AUTOSAR XML (schema 4-0-3)
package /ComponentTypes
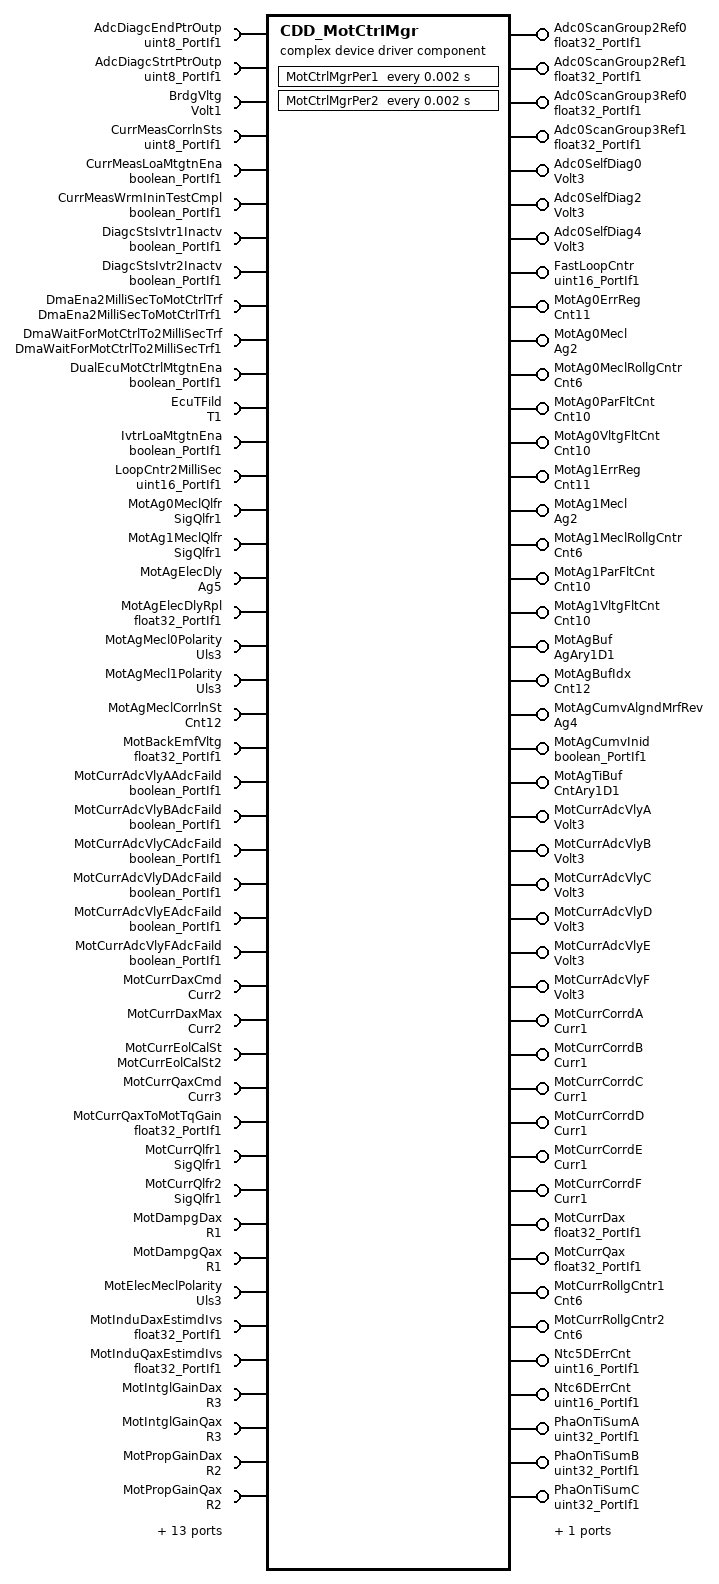
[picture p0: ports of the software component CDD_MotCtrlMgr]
  complex device driver sw component type CDD_MotCtrlMgr
    45 x provide port:
      Adc0ScanGroup2Ref0: nonqueued-sender-com-spec{data-element=Val, init-value=0}, provided-interface=float32_PortIf1
      Adc0ScanGroup2Ref1: nonqueued-sender-com-spec{data-element=Val, init-value=0}, provided-interface=float32_PortIf1
      Adc0ScanGroup3Ref0: nonqueued-sender-com-spec{data-element=Val, init-value=0}, provided-interface=float32_PortIf1
      Adc0ScanGroup3Ref1: nonqueued-sender-com-spec{data-element=Val, init-value=0}, provided-interface=float32_PortIf1
      Adc0SelfDiag0: nonqueued-sender-com-spec{data-element=Val, init-value=0}, provided-interface=Volt3
      Adc0SelfDiag2: nonqueued-sender-com-spec{data-element=Val, init-value=0}, provided-interface=Volt3
      Adc0SelfDiag4: nonqueued-sender-com-spec{data-element=Val, init-value=0}, provided-interface=Volt3
      FastLoopCntr: nonqueued-sender-com-spec{data-element=Val, init-value=0}, provided-interface=uint16_PortIf1
      MotAg0ErrReg: nonqueued-sender-com-spec{data-element=Val, init-value=0}, provided-interface=Cnt11
      MotAg0Mecl: nonqueued-sender-com-spec{data-element=Val, init-value=0}, provided-interface=Ag2
      MotAg0MeclRollgCntr: nonqueued-sender-com-spec{data-element=Val, init-value=0}, provided-interface=Cnt6
      MotAg0ParFltCnt: nonqueued-sender-com-spec{data-element=Val, init-value=0}, provided-interface=Cnt10
      MotAg0VltgFltCnt: nonqueued-sender-com-spec{data-element=Val, init-value=0}, provided-interface=Cnt10
      MotAg1ErrReg: nonqueued-sender-com-spec{data-element=Val, init-value=0}, provided-interface=Cnt11
      MotAg1Mecl: nonqueued-sender-com-spec{data-element=Val, init-value=0}, provided-interface=Ag2
      MotAg1MeclRollgCntr: nonqueued-sender-com-spec{data-element=Val, init-value=0}, provided-interface=Cnt6
      MotAg1ParFltCnt: nonqueued-sender-com-spec{data-element=Val, init-value=0}, provided-interface=Cnt10
      MotAg1VltgFltCnt: nonqueued-sender-com-spec{data-element=Val, init-value=0}, provided-interface=Cnt10
      MotAgBuf: nonqueued-sender-com-spec{data-element=Ary1D, init-value=8 x 0}, provided-interface=AgAry1D1
      MotAgBufIdx: nonqueued-sender-com-spec{data-element=Val, init-value=0}, provided-interface=Cnt12
      MotAgCumvAlgndMrfRev: nonqueued-sender-com-spec{data-element=Val, init-value=0}, provided-interface=Ag4
      MotAgCumvInid: nonqueued-sender-com-spec{data-element=Logl, init-value=0}, provided-interface=boolean_PortIf1
      MotAgTiBuf: nonqueued-sender-com-spec{data-element=Ary1D, init-value=8 x 0}, provided-interface=CntAry1D1
      MotCurrAdcVlyA: nonqueued-sender-com-spec{data-element=Val, init-value=0}, provided-interface=Volt3
      MotCurrAdcVlyB: nonqueued-sender-com-spec{data-element=Val, init-value=0}, provided-interface=Volt3
      MotCurrAdcVlyC: nonqueued-sender-com-spec{data-element=Val, init-value=0}, provided-interface=Volt3
      MotCurrAdcVlyD: nonqueued-sender-com-spec{data-element=Val, init-value=0}, provided-interface=Volt3
      MotCurrAdcVlyE: nonqueued-sender-com-spec{data-element=Val, init-value=0}, provided-interface=Volt3
      MotCurrAdcVlyF: nonqueued-sender-com-spec{data-element=Val, init-value=0}, provided-interface=Volt3
      MotCurrCorrdA: nonqueued-sender-com-spec{data-element=Val, init-value=0}, provided-interface=Curr1
      MotCurrCorrdB: nonqueued-sender-com-spec{data-element=Val, init-value=0}, provided-interface=Curr1
      MotCurrCorrdC: nonqueued-sender-com-spec{data-element=Val, init-value=0}, provided-interface=Curr1
      MotCurrCorrdD: nonqueued-sender-com-spec{data-element=Val, init-value=0}, provided-interface=Curr1
      MotCurrCorrdE: nonqueued-sender-com-spec{data-element=Val, init-value=0}, provided-interface=Curr1
      MotCurrCorrdF: nonqueued-sender-com-spec{data-element=Val, init-value=0}, provided-interface=Curr1
      MotCurrDax: nonqueued-sender-com-spec{data-element=Val, init-value=0}, provided-interface=float32_PortIf1
      MotCurrQax: nonqueued-sender-com-spec{data-element=Val, init-value=0}, provided-interface=float32_PortIf1
      MotCurrRollgCntr1: nonqueued-sender-com-spec{data-element=Val, init-value=0}, provided-interface=Cnt6
      MotCurrRollgCntr2: nonqueued-sender-com-spec{data-element=Val, init-value=0}, provided-interface=Cnt6
      Ntc5DErrCnt: nonqueued-sender-com-spec{data-element=Val, init-value=0}, provided-interface=uint16_PortIf1
      Ntc6DErrCnt: nonqueued-sender-com-spec{data-element=Val, init-value=0}, provided-interface=uint16_PortIf1
      PhaOnTiSumA: nonqueued-sender-com-spec{data-element=Val, init-value=0}, provided-interface=uint32_PortIf1
      PhaOnTiSumB: nonqueued-sender-com-spec{data-element=Val, init-value=0}, provided-interface=uint32_PortIf1
      PhaOnTiSumC: nonqueued-sender-com-spec{data-element=Val, init-value=0}, provided-interface=uint32_PortIf1
      SlowLoopCntr: nonqueued-sender-com-spec{data-element=Val, init-value=0}, provided-interface=uint16_PortIf1
    57 x require port:
      AdcDiagcEndPtrOutp: nonqueued-receiver-com-spec{data-element=Val, filter=data-filter-type=ALWAYS, init-value=23}, required-interface=uint8_PortIf1
      AdcDiagcStrtPtrOutp: nonqueued-receiver-com-spec{data-element=Val, filter=data-filter-type=ALWAYS, init-value=21}, required-interface=uint8_PortIf1
      BrdgVltg: nonqueued-receiver-com-spec{data-element=Val, filter=data-filter-type=ALWAYS, init-value=6}, required-interface=Volt1
      CurrMeasCorrlnSts: nonqueued-receiver-com-spec{data-element=Val, filter=data-filter-type=ALWAYS, init-value=63}, required-interface=uint8_PortIf1
      CurrMeasLoaMtgtnEna: nonqueued-receiver-com-spec{data-element=Logl, filter=data-filter-type=ALWAYS, init-value=0}, required-interface=boolean_PortIf1
      CurrMeasWrmIninTestCmpl: nonqueued-receiver-com-spec{data-element=Logl, filter=data-filter-type=ALWAYS, init-value=0}, required-interface=boolean_PortIf1
      DiagcStsIvtr1Inactv: nonqueued-receiver-com-spec{data-element=Logl, filter=data-filter-type=ALWAYS, init-value=0}, required-interface=boolean_PortIf1
      DiagcStsIvtr2Inactv: nonqueued-receiver-com-spec{data-element=Logl, filter=data-filter-type=ALWAYS, init-value=0}, required-interface=boolean_PortIf1
      DmaEna2MilliSecToMotCtrlTrf: client-com-spec=Oper, required-interface=DmaEna2MilliSecToMotCtrlTrf1
      DmaWaitForMotCtrlTo2MilliSecTrf: client-com-spec=Oper, required-interface=DmaWaitForMotCtrlTo2MilliSecTrf1
      DualEcuMotCtrlMtgtnEna: nonqueued-receiver-com-spec{data-element=Logl, filter=data-filter-type=ALWAYS, init-value=0}, required-interface=boolean_PortIf1
      EcuTFild: nonqueued-receiver-com-spec{data-element=Val, filter=data-filter-type=ALWAYS, init-value=25}, required-interface=T1
      IvtrLoaMtgtnEna: nonqueued-receiver-com-spec{data-element=Logl, filter=data-filter-type=ALWAYS, init-value=0}, required-interface=boolean_PortIf1
      LoopCntr2MilliSec: nonqueued-receiver-com-spec{data-element=Val, filter=data-filter-type=ALWAYS, init-value=0}, required-interface=uint16_PortIf1
      MotAg0MeclQlfr: nonqueued-receiver-com-spec{data-element=Val, filter=data-filter-type=ALWAYS, init-value=0}, required-interface=SigQlfr1
      MotAg1MeclQlfr: nonqueued-receiver-com-spec{data-element=Val, filter=data-filter-type=ALWAYS, init-value=0}, required-interface=SigQlfr1
      MotAgElecDly: nonqueued-receiver-com-spec{data-element=Val, filter=data-filter-type=ALWAYS, init-value=0}, required-interface=Ag5
      MotAgElecDlyRpl: nonqueued-receiver-com-spec{data-element=Val, filter=data-filter-type=ALWAYS, init-value=0}, required-interface=float32_PortIf1
      MotAgMecl0Polarity: nonqueued-receiver-com-spec{data-element=Val, filter=data-filter-type=ALWAYS, init-value=1}, required-interface=Uls3
      MotAgMecl1Polarity: nonqueued-receiver-com-spec{data-element=Val, filter=data-filter-type=ALWAYS, init-value=1}, required-interface=Uls3
      MotAgMeclCorrlnSt: nonqueued-receiver-com-spec{data-element=Val, filter=data-filter-type=ALWAYS, init-value=7}, required-interface=Cnt12
      MotBackEmfVltg: nonqueued-receiver-com-spec{data-element=Val, filter=data-filter-type=ALWAYS, init-value=0}, required-interface=float32_PortIf1
      MotCurrAdcVlyAAdcFaild: nonqueued-receiver-com-spec{data-element=Logl, filter=data-filter-type=ALWAYS, init-value=0}, required-interface=boolean_PortIf1
      MotCurrAdcVlyBAdcFaild: nonqueued-receiver-com-spec{data-element=Logl, filter=data-filter-type=ALWAYS, init-value=0}, required-interface=boolean_PortIf1
      MotCurrAdcVlyCAdcFaild: nonqueued-receiver-com-spec{data-element=Logl, filter=data-filter-type=ALWAYS, init-value=0}, required-interface=boolean_PortIf1
      MotCurrAdcVlyDAdcFaild: nonqueued-receiver-com-spec{data-element=Logl, filter=data-filter-type=ALWAYS, init-value=0}, required-interface=boolean_PortIf1
      MotCurrAdcVlyEAdcFaild: nonqueued-receiver-com-spec{data-element=Logl, filter=data-filter-type=ALWAYS, init-value=0}, required-interface=boolean_PortIf1
      MotCurrAdcVlyFAdcFaild: nonqueued-receiver-com-spec{data-element=Logl, filter=data-filter-type=ALWAYS, init-value=0}, required-interface=boolean_PortIf1
      MotCurrDaxCmd: nonqueued-receiver-com-spec{data-element=Val, filter=data-filter-type=ALWAYS, init-value=0}, required-interface=Curr2
      MotCurrDaxMax: nonqueued-receiver-com-spec{data-element=Val, filter=data-filter-type=ALWAYS, init-value=0}, required-interface=Curr2
      MotCurrEolCalSt: nonqueued-receiver-com-spec{data-element=Val, filter=data-filter-type=ALWAYS, init-value=0}, required-interface=MotCurrEolCalSt2
      MotCurrQaxCmd: nonqueued-receiver-com-spec{data-element=Val, filter=data-filter-type=ALWAYS, init-value=0}, required-interface=Curr3
      MotCurrQaxToMotTqGain: nonqueued-receiver-com-spec{data-element=Val, filter=data-filter-type=ALWAYS, init-value=0.021651}, required-interface=float32_PortIf1
      MotCurrQlfr1: nonqueued-receiver-com-spec{data-element=Val, filter=data-filter-type=ALWAYS, init-value=0}, required-interface=SigQlfr1
      MotCurrQlfr2: nonqueued-receiver-com-spec{data-element=Val, filter=data-filter-type=ALWAYS, init-value=0}, required-interface=SigQlfr1
      MotDampgDax: nonqueued-receiver-com-spec{data-element=Val, filter=data-filter-type=ALWAYS, init-value=0}, required-interface=R1
      MotDampgQax: nonqueued-receiver-com-spec{data-element=Val, filter=data-filter-type=ALWAYS, init-value=0}, required-interface=R1
      MotElecMeclPolarity: nonqueued-receiver-com-spec{data-element=Val, filter=data-filter-type=ALWAYS, init-value=1}, required-interface=Uls3
      MotInduDaxEstimdIvs: nonqueued-receiver-com-spec{data-element=Val, filter=data-filter-type=ALWAYS, init-value=8411}, required-interface=float32_PortIf1
      MotInduQaxEstimdIvs: nonqueued-receiver-com-spec{data-element=Val, filter=data-filter-type=ALWAYS, init-value=8411}, required-interface=float32_PortIf1
      MotIntglGainDax: nonqueued-receiver-com-spec{data-element=Val, filter=data-filter-type=ALWAYS, init-value=0}, required-interface=R3
      MotIntglGainQax: nonqueued-receiver-com-spec{data-element=Val, filter=data-filter-type=ALWAYS, init-value=0}, required-interface=R3
      MotPropGainDax: nonqueued-receiver-com-spec{data-element=Val, filter=data-filter-type=ALWAYS, init-value=0}, required-interface=R2
      MotPropGainQax: nonqueued-receiver-com-spec{data-element=Val, filter=data-filter-type=ALWAYS, init-value=0}, required-interface=R2
      MotReacncDax: nonqueued-receiver-com-spec{data-element=Val, filter=data-filter-type=ALWAYS, init-value=0}, required-interface=R5
      MotReacncQax: nonqueued-receiver-com-spec{data-element=Val, filter=data-filter-type=ALWAYS, init-value=0}, required-interface=R5
      MotREstimd: nonqueued-receiver-com-spec{data-element=Val, filter=data-filter-type=ALWAYS, init-value=0.005}, required-interface=float32_PortIf1
      MotTqRplCoggOrder1Mgn: nonqueued-receiver-com-spec{data-element=Val, filter=data-filter-type=ALWAYS, init-value=0}, required-interface=float32_PortIf1
      MotTqRplCoggOrder1Pha: nonqueued-receiver-com-spec{data-element=Val, filter=data-filter-type=ALWAYS, init-value=0}, required-interface=float32_PortIf1
      MotTqRplCoggOrder2Mgn: nonqueued-receiver-com-spec{data-element=Val, filter=data-filter-type=ALWAYS, init-value=0}, required-interface=float32_PortIf1
      MotTqRplCoggOrder2Pha: nonqueued-receiver-com-spec{data-element=Val, filter=data-filter-type=ALWAYS, init-value=0}, required-interface=float32_PortIf1
      MotTqRplCoggOrder3Mgn: nonqueued-receiver-com-spec{data-element=Val, filter=data-filter-type=ALWAYS, init-value=0}, required-interface=float32_PortIf1
      MotTqRplCoggOrder3Pha: nonqueued-receiver-com-spec{data-element=Val, filter=data-filter-type=ALWAYS, init-value=0}, required-interface=float32_PortIf1
      MotVelMrf: nonqueued-receiver-com-spec{data-element=Val, filter=data-filter-type=ALWAYS, init-value=0}, required-interface=Vel1
      MotVltgDaxFf: nonqueued-receiver-com-spec{data-element=Val, filter=data-filter-type=ALWAYS, init-value=0}, required-interface=Volt6
      MotVltgQaxFf: nonqueued-receiver-com-spec{data-element=Val, filter=data-filter-type=ALWAYS, init-value=0}, required-interface=Volt6
      SysSt: nonqueued-receiver-com-spec{data-element=Val, filter=data-filter-type=ALWAYS, init-value=3}, required-interface=SysSt1
    behavior CDD_MotCtrlMgr_InternalBehavior: data-type-mapping=Nexteer
      timing event TMT_MotCtrlMgrPer1: start-on-event=MotCtrlMgrPer1, period=0.002
      timing event TMT_MotCtrlMgrPer2: start-on-event=MotCtrlMgrPer2, period=0.002
      runnable MotCtrlMgrPer1
        data-send-points:
          45 x access:
            SEND_Adc0ScanGroup2Ref0_Val: accessed-variable=Adc0ScanGroup2Ref0.Val
            SEND_Adc0ScanGroup2Ref1_Val: accessed-variable=Adc0ScanGroup2Ref1.Val
            SEND_Adc0ScanGroup3Ref0_Val: accessed-variable=Adc0ScanGroup3Ref0.Val
            SEND_Adc0ScanGroup3Ref1_Val: accessed-variable=Adc0ScanGroup3Ref1.Val
            SEND_Adc0SelfDiag0_Val: accessed-variable=Adc0SelfDiag0.Val
            SEND_Adc0SelfDiag2_Val: accessed-variable=Adc0SelfDiag2.Val
            SEND_Adc0SelfDiag4_Val: accessed-variable=Adc0SelfDiag4.Val
            SEND_FastLoopCntr_Val: accessed-variable=FastLoopCntr.Val
            SEND_MotAg0ErrReg_Val: accessed-variable=MotAg0ErrReg.Val
            SEND_MotAg0Mecl_Val: accessed-variable=MotAg0Mecl.Val
            SEND_MotAg0MeclRollgCntr_Val: accessed-variable=MotAg0MeclRollgCntr.Val
            SEND_MotAg0ParFltCnt_Val: accessed-variable=MotAg0ParFltCnt.Val
            SEND_MotAg0VltgFltCnt_Val: accessed-variable=MotAg0VltgFltCnt.Val
            SEND_MotAg1ErrReg_Val: accessed-variable=MotAg1ErrReg.Val
            SEND_MotAg1Mecl_Val: accessed-variable=MotAg1Mecl.Val
            SEND_MotAg1MeclRollgCntr_Val: accessed-variable=MotAg1MeclRollgCntr.Val
            SEND_MotAg1ParFltCnt_Val: accessed-variable=MotAg1ParFltCnt.Val
            SEND_MotAg1VltgFltCnt_Val: accessed-variable=MotAg1VltgFltCnt.Val
            SEND_MotAgBuf_Ary1D: accessed-variable=MotAgBuf.Ary1D
            SEND_MotAgBufIdx_Val: accessed-variable=MotAgBufIdx.Val
            SEND_MotAgCumvAlgndMrfRev_Val: accessed-variable=MotAgCumvAlgndMrfRev.Val
            SEND_MotAgCumvInid_Logl: accessed-variable=MotAgCumvInid.Logl
            SEND_MotAgTiBuf_Ary1D: accessed-variable=MotAgTiBuf.Ary1D
            SEND_MotCurrAdcVlyA_Val: accessed-variable=MotCurrAdcVlyA.Val
            SEND_MotCurrAdcVlyB_Val: accessed-variable=MotCurrAdcVlyB.Val
            SEND_MotCurrAdcVlyC_Val: accessed-variable=MotCurrAdcVlyC.Val
            SEND_MotCurrAdcVlyD_Val: accessed-variable=MotCurrAdcVlyD.Val
            SEND_MotCurrAdcVlyE_Val: accessed-variable=MotCurrAdcVlyE.Val
            SEND_MotCurrAdcVlyF_Val: accessed-variable=MotCurrAdcVlyF.Val
            SEND_MotCurrCorrdA_Val: accessed-variable=MotCurrCorrdA.Val
            SEND_MotCurrCorrdB_Val: accessed-variable=MotCurrCorrdB.Val
            SEND_MotCurrCorrdC_Val: accessed-variable=MotCurrCorrdC.Val
            SEND_MotCurrCorrdD_Val: accessed-variable=MotCurrCorrdD.Val
            SEND_MotCurrCorrdE_Val: accessed-variable=MotCurrCorrdE.Val
            SEND_MotCurrCorrdF_Val: accessed-variable=MotCurrCorrdF.Val
            SEND_MotCurrDax_Val: accessed-variable=MotCurrDax.Val
            SEND_MotCurrQax_Val: accessed-variable=MotCurrQax.Val
            SEND_MotCurrRollgCntr1_Val: accessed-variable=MotCurrRollgCntr1.Val
            SEND_MotCurrRollgCntr2_Val: accessed-variable=MotCurrRollgCntr2.Val
            SEND_Ntc5DErrCnt_Val: accessed-variable=Ntc5DErrCnt.Val
            SEND_Ntc6DErrCnt_Val: accessed-variable=Ntc6DErrCnt.Val
            SEND_PhaOnTiSumA_Val: accessed-variable=PhaOnTiSumA.Val
            SEND_PhaOnTiSumB_Val: accessed-variable=PhaOnTiSumB.Val
            SEND_PhaOnTiSumC_Val: accessed-variable=PhaOnTiSumC.Val
            SEND_SlowLoopCntr_Val: accessed-variable=SlowLoopCntr.Val
        sync call SC_DmaWaitForMotCtrlTo2MilliSecTrf_Oper: operation=DmaWaitForMotCtrlTo2MilliSecTrf.Oper, timeout=0
      runnable MotCtrlMgrPer2
        data-receive-point-by-arguments:
          55 x access:
            REC_AdcDiagcEndPtrOutp_Val: accessed-variable=AdcDiagcEndPtrOutp.Val
            REC_AdcDiagcStrtPtrOutp_Val: accessed-variable=AdcDiagcStrtPtrOutp.Val
            REC_BrdgVltg_Val: accessed-variable=BrdgVltg.Val
            REC_CurrMeasCorrlnSts_Val: accessed-variable=CurrMeasCorrlnSts.Val
            REC_CurrMeasLoaMtgtnEna_Logl: accessed-variable=CurrMeasLoaMtgtnEna.Logl
            REC_DiagcStsIvtr1Inactv_Logl: accessed-variable=DiagcStsIvtr1Inactv.Logl
            REC_DiagcStsIvtr2Inactv_Logl: accessed-variable=DiagcStsIvtr2Inactv.Logl
            REC_DualEcuMotCtrlMtgtnEna_Logl: accessed-variable=DualEcuMotCtrlMtgtnEna.Logl
            REC_EcuTFild_Val: accessed-variable=EcuTFild.Val
            REC_IvtrLoaMtgtnEna_Logl: accessed-variable=IvtrLoaMtgtnEna.Logl
            REC_LoopCntr2MilliSec_Val: accessed-variable=LoopCntr2MilliSec.Val
            REC_MotAg0MeclQlfr_Val: accessed-variable=MotAg0MeclQlfr.Val
            REC_MotAg1MeclQlfr_Val: accessed-variable=MotAg1MeclQlfr.Val
            REC_MotAgElecDly_Val: accessed-variable=MotAgElecDly.Val
            REC_MotAgElecDlyRpl_Val: accessed-variable=MotAgElecDlyRpl.Val
            REC_MotAgMecl0Polarity_Val: accessed-variable=MotAgMecl0Polarity.Val
            REC_MotAgMecl1Polarity_Val: accessed-variable=MotAgMecl1Polarity.Val
            REC_MotAgMeclCorrlnSt_Val: accessed-variable=MotAgMeclCorrlnSt.Val
            REC_MotBackEmfVltg_Val: accessed-variable=MotBackEmfVltg.Val
            REC_MotCtrlCurrMeasWrmIninTestCmpl_Logl: accessed-variable=CurrMeasWrmIninTestCmpl.Logl
            REC_MotCurrAdcVlyAAdcFaild_Logl: accessed-variable=MotCurrAdcVlyAAdcFaild.Logl
            REC_MotCurrAdcVlyBAdcFaild_Logl: accessed-variable=MotCurrAdcVlyBAdcFaild.Logl
            REC_MotCurrAdcVlyCAdcFaild_Logl: accessed-variable=MotCurrAdcVlyCAdcFaild.Logl
            REC_MotCurrAdcVlyDAdcFaild_Logl: accessed-variable=MotCurrAdcVlyDAdcFaild.Logl
            REC_MotCurrAdcVlyEAdcFaild_Logl: accessed-variable=MotCurrAdcVlyEAdcFaild.Logl
            REC_MotCurrAdcVlyFAdcFaild_Logl: accessed-variable=MotCurrAdcVlyFAdcFaild.Logl
            REC_MotCurrDaxCmd_Val: accessed-variable=MotCurrDaxCmd.Val
            REC_MotCurrDaxMax_Val: accessed-variable=MotCurrDaxMax.Val
            REC_MotCurrEolCalSt_Val: accessed-variable=MotCurrEolCalSt.Val
            REC_MotCurrQaxCmd_Val: accessed-variable=MotCurrQaxCmd.Val
            REC_MotCurrQaxToMotTqGain_Val: accessed-variable=MotCurrQaxToMotTqGain.Val
            REC_MotCurrQlfr1_Val: accessed-variable=MotCurrQlfr1.Val
            REC_MotCurrQlfr2_Val: accessed-variable=MotCurrQlfr2.Val
            REC_MotDampgDax_Val: accessed-variable=MotDampgDax.Val
            REC_MotDampgQax_Val: accessed-variable=MotDampgQax.Val
            REC_MotElecMeclPolarity_Val: accessed-variable=MotElecMeclPolarity.Val
            REC_MotInduDaxEstimdIvs_Val: accessed-variable=MotInduDaxEstimdIvs.Val
            REC_MotInduQaxEstimdIvs_Val: accessed-variable=MotInduQaxEstimdIvs.Val
            REC_MotIntglGainDax_Val: accessed-variable=MotIntglGainDax.Val
            REC_MotIntglGainQax_Val: accessed-variable=MotIntglGainQax.Val
            REC_MotPropGainDax_Val: accessed-variable=MotPropGainDax.Val
            REC_MotPropGainQax_Val: accessed-variable=MotPropGainQax.Val
            REC_MotReacncDax_Val: accessed-variable=MotReacncDax.Val
            REC_MotReacncQax_Val: accessed-variable=MotReacncQax.Val
            REC_MotREstimd_Val: accessed-variable=MotREstimd.Val
            REC_MotTqRplCoggOrder1Mgn_Val: accessed-variable=MotTqRplCoggOrder1Mgn.Val
            REC_MotTqRplCoggOrder1Pha_Val: accessed-variable=MotTqRplCoggOrder1Pha.Val
            REC_MotTqRplCoggOrder2Mgn_Val: accessed-variable=MotTqRplCoggOrder2Mgn.Val
            REC_MotTqRplCoggOrder2Pha_Val: accessed-variable=MotTqRplCoggOrder2Pha.Val
            REC_MotTqRplCoggOrder3Mgn_Val: accessed-variable=MotTqRplCoggOrder3Mgn.Val
            REC_MotTqRplCoggOrder3Pha_Val: accessed-variable=MotTqRplCoggOrder3Pha.Val
            REC_MotVelMrf_Val: accessed-variable=MotVelMrf.Val
            REC_MotVltgDaxFf_Val: accessed-variable=MotVltgDaxFf.Val
            REC_MotVltgQaxFf_Val: accessed-variable=MotVltgQaxFf.Val
            REC_SysSt_Val: accessed-variable=SysSt.Val
        sync call SC_DmaEna2MilliSecToMotCtrlTrf_Oper: operation=DmaEna2MilliSecToMotCtrlTrf.Oper, timeout=0
  swc implementation CDD_MotCtrlMgr_Implementation: behavior=CDD_MotCtrlMgr_InternalBehavior
    code-descriptors:
      code Default: artifact-descriptors=autosar-engineering-object={short-label=Default, category=SWSRC}
